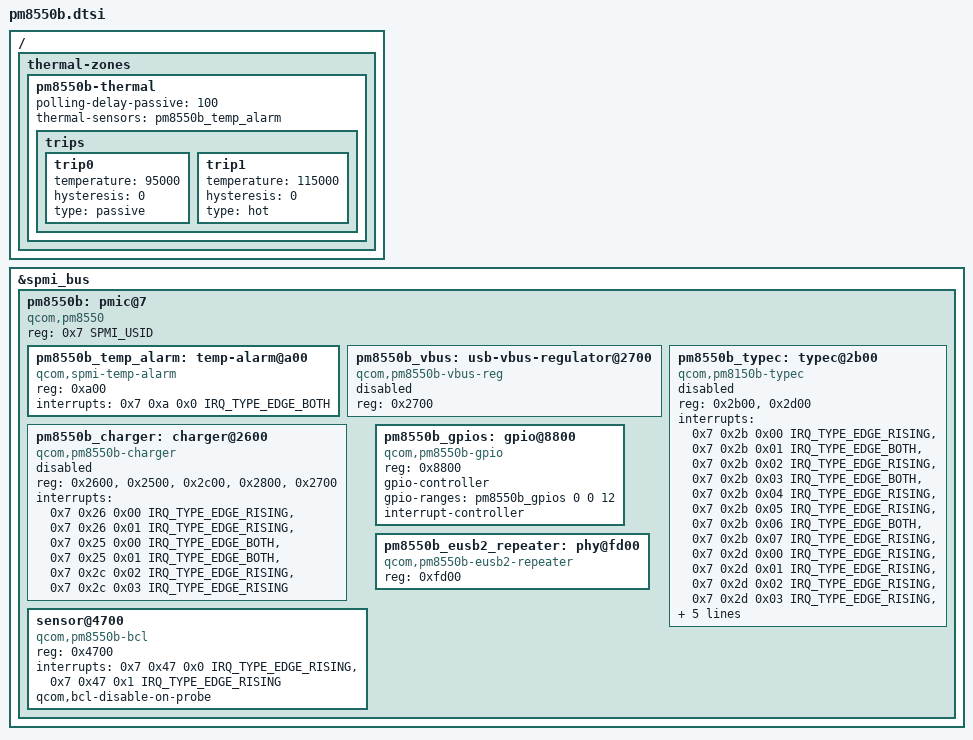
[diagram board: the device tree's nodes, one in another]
// SPDX-License-Identifier: BSD-3-Clause
/*
 * Copyright (c) 2022, Linaro Limited
 */

#include <dt-bindings/interrupt-controller/irq.h>
#include <dt-bindings/spmi/spmi.h>

/ {
	thermal-zones {
		pm8550b-thermal {
			polling-delay-passive = <100>;

			thermal-sensors = <&pm8550b_temp_alarm>;

			trips {
				trip0 {
					temperature = <95000>;
					hysteresis = <0>;
					type = "passive";
				};

				trip1 {
					temperature = <115000>;
					hysteresis = <0>;
					type = "hot";
				};
			};
		};
	};
};


&spmi_bus {
	pm8550b: pmic@7 {
		compatible = "qcom,pm8550", "qcom,spmi-pmic";
		reg = <0x7 SPMI_USID>;
		#address-cells = <1>;
		#size-cells = <0>;

		pm8550b_temp_alarm: temp-alarm@a00 {
			compatible = "qcom,spmi-temp-alarm";
			reg = <0xa00>;
			interrupts = <0x7 0xa 0x0 IRQ_TYPE_EDGE_BOTH>;
			#thermal-sensor-cells = <0>;
		};

		pm8550b_vbus: usb-vbus-regulator@2700 {
			compatible = "qcom,pm8550b-vbus-reg";
			status = "disabled";
			reg = <0x2700>;
		};

		pm8550b_typec: typec@2b00 {
			// Owns 0x2900 USB Power for UVP
			compatible = "qcom,pm8150b-typec";
			status = "disabled";
			reg = <0x2b00>,
			      <0x2d00>;
			interrupts = <0x7 0x2b 0x00 IRQ_TYPE_EDGE_RISING>,
				     <0x7 0x2b 0x01 IRQ_TYPE_EDGE_BOTH>,
				     <0x7 0x2b 0x02 IRQ_TYPE_EDGE_RISING>,
				     <0x7 0x2b 0x03 IRQ_TYPE_EDGE_BOTH>,
				     <0x7 0x2b 0x04 IRQ_TYPE_EDGE_RISING>,
				     <0x7 0x2b 0x05 IRQ_TYPE_EDGE_RISING>,
				     <0x7 0x2b 0x06 IRQ_TYPE_EDGE_BOTH>,
				     <0x7 0x2b 0x07 IRQ_TYPE_EDGE_RISING>,
				     <0x7 0x2d 0x00 IRQ_TYPE_EDGE_RISING>,
				     <0x7 0x2d 0x01 IRQ_TYPE_EDGE_RISING>,
				     <0x7 0x2d 0x02 IRQ_TYPE_EDGE_RISING>,
				     <0x7 0x2d 0x03 IRQ_TYPE_EDGE_RISING>,
				     <0x7 0x2d 0x04 IRQ_TYPE_EDGE_RISING>,
				     <0x7 0x2d 0x05 IRQ_TYPE_EDGE_RISING>,
				     <0x7 0x2d 0x06 IRQ_TYPE_EDGE_RISING>,
				     <0x7 0x2d 0x07 IRQ_TYPE_EDGE_RISING>;
			interrupt-names = "or-rid-detect-change",
					  "vpd-detect",
					  "cc-state-change",
					  "vconn-oc",
					  "vbus-change",
					  "attach-detach",
					  "legacy-cable-detect",
					  "try-snk-src-detect",
					  "sig-tx",
					  "sig-rx",
					  "msg-tx",
					  "msg-rx",
					  "msg-tx-failed",
					  "msg-tx-discarded",
					  "msg-rx-discarded",
					  "fr-swap";
			vdd-vbus-supply = <&pm8550b_vbus>;
		};

		pm8550b_charger: charger@2600 {
			// Owns 0x2800 for JEITA setup
			// Owns 0x4F00 to disable it
			// Uses 0x2700 To check USB ICL for AICL complete
			compatible = "qcom,pm8550b-charger";
			status = "disabled";
			reg = <0x2600>,
			      <0x2500>,
				  <0x2c00>,
                  <0x2800>,
                  <0x2700>;
			interrupts = <0x7 0x26 0x00 IRQ_TYPE_EDGE_RISING>,
				     <0x7 0x26 0x01 IRQ_TYPE_EDGE_RISING>,
					 <0x7 0x25 0x00 IRQ_TYPE_EDGE_BOTH>,
					 <0x7 0x25 0x01 IRQ_TYPE_EDGE_BOTH>,
					 <0x7 0x2c 0x02 IRQ_TYPE_EDGE_RISING>,
					 <0x7 0x2c 0x03 IRQ_TYPE_EDGE_RISING>;
			interrupt-names = "charging-state-change",
					  "charger-error",
					  "charging-path-change",
					  "full-duty-charge-mode",
					  "aicl-fail",
					  "aicl-done";
		};

		sensor@4700 {
			compatible = "qcom,pm8550b-bcl";
			reg = <0x4700>;
			interrupts = <0x7 0x47 0x0 IRQ_TYPE_EDGE_RISING>,
				     <0x7 0x47 0x1 IRQ_TYPE_EDGE_RISING>;
			interrupt-names = "max-min",
					  "critical";
			qcom,bcl-disable-on-probe;
		};

		pm8550b_gpios: gpio@8800 {
			compatible = "qcom,pm8550b-gpio", "qcom,spmi-gpio";
			reg = <0x8800>;
			gpio-controller;
			gpio-ranges = <&pm8550b_gpios 0 0 12>;
			#gpio-cells = <2>;
			interrupt-controller;
			#interrupt-cells = <2>;
		};

		pm8550b_eusb2_repeater: phy@fd00 {
			compatible = "qcom,pm8550b-eusb2-repeater";
			reg = <0xfd00>;
			#phy-cells = <0>;
		};
	};
};
